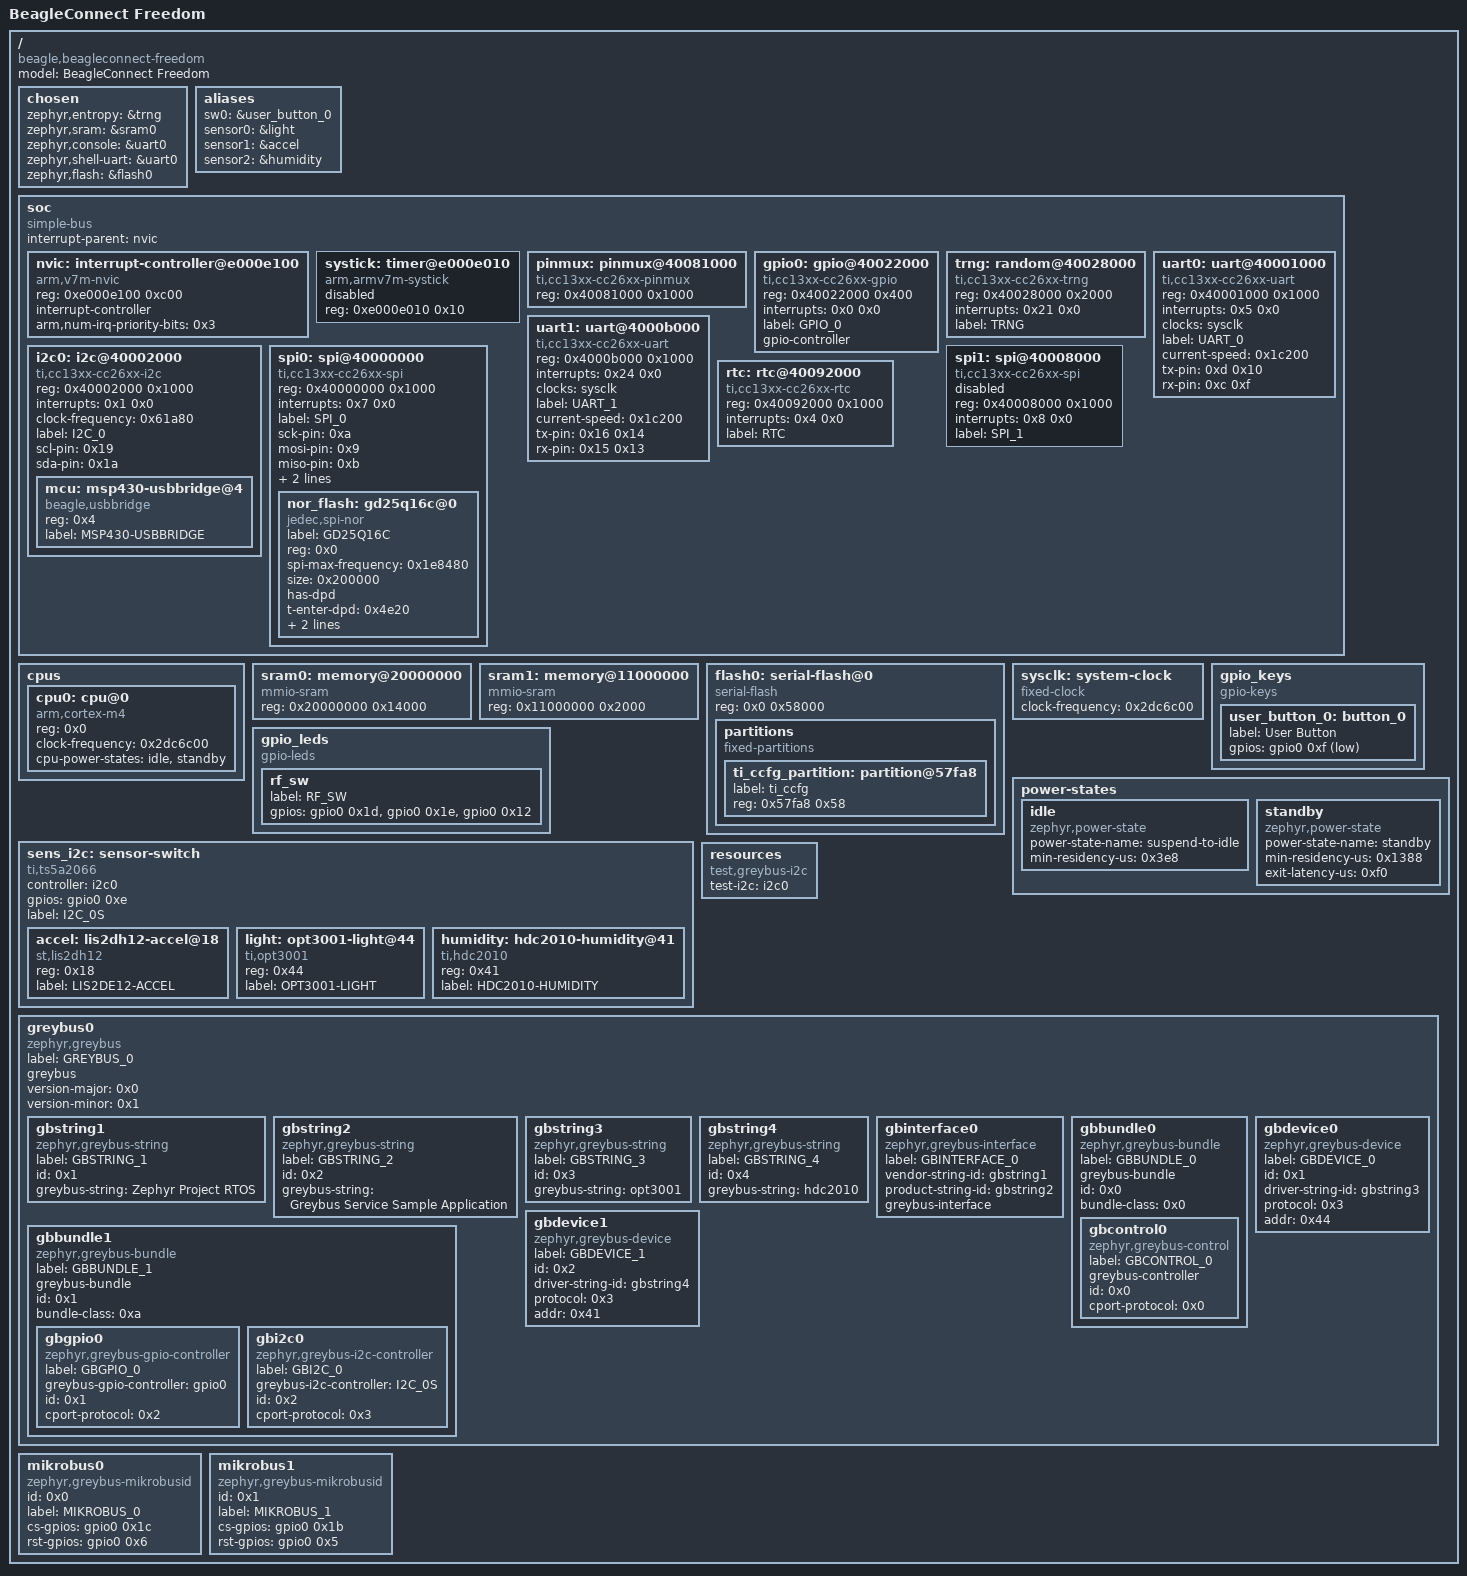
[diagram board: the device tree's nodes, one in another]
/dts-v1/;

/ {
	#address-cells = < 0x1 >;
	#size-cells = < 0x1 >;
	model = "BeagleConnect Freedom";
	compatible = "beagle,beagleconnect-freedom";
	chosen {
		zephyr,entropy = &trng;
		zephyr,sram = &sram0;
		zephyr,console = &uart0;
		zephyr,shell-uart = &uart0;
		zephyr,flash = &flash0;
	};
	aliases {
		sw0 = &user_button_0;
		sensor0 = &light;
		sensor1 = &accel;
		sensor2 = &humidity;
	};
	soc {
		#address-cells = < 0x1 >;
		#size-cells = < 0x1 >;
		compatible = "simple-bus";
		interrupt-parent = < &nvic >;
		ranges;
		nvic: interrupt-controller@e000e100 {
			#address-cells = < 0x1 >;
			compatible = "arm,v7m-nvic";
			reg = < 0xe000e100 0xc00 >;
			interrupt-controller;
			#interrupt-cells = < 0x2 >;
			arm,num-irq-priority-bits = < 0x3 >;
			phandle = < 0x1 >;
		};
		systick: timer@e000e010 {
			compatible = "arm,armv7m-systick";
			reg = < 0xe000e010 0x10 >;
			status = "disabled";
		};
		pinmux: pinmux@40081000 {
			compatible = "ti,cc13xx-cc26xx-pinmux";
			reg = < 0x40081000 0x1000 >;
		};
		gpio0: gpio@40022000 {
			compatible = "ti,cc13xx-cc26xx-gpio";
			reg = < 0x40022000 0x400 >;
			interrupts = < 0x0 0x0 >;
			status = "okay";
			label = "GPIO_0";
			gpio-controller;
			#gpio-cells = < 0x2 >;
			phandle = < 0x3 >;
		};
		trng: random@40028000 {
			compatible = "ti,cc13xx-cc26xx-trng";
			reg = < 0x40028000 0x2000 >;
			interrupts = < 0x21 0x0 >;
			status = "okay";
			label = "TRNG";
		};
		uart0: uart@40001000 {
			compatible = "ti,cc13xx-cc26xx-uart";
			reg = < 0x40001000 0x1000 >;
			interrupts = < 0x5 0x0 >;
			clocks = < &sysclk >;
			status = "okay";
			label = "UART_0";
			current-speed = < 0x1c200 >;
			tx-pin = < 0xd 0x10 >;
			rx-pin = < 0xc 0xf >;
		};
		uart1: uart@4000b000 {
			compatible = "ti,cc13xx-cc26xx-uart";
			reg = < 0x4000b000 0x1000 >;
			interrupts = < 0x24 0x0 >;
			clocks = < &sysclk >;
			status = "okay";
			label = "UART_1";
			current-speed = < 0x1c200 >;
			tx-pin = < 0x16 0x14 >;
			rx-pin = < 0x15 0x13 >;
		};
		i2c0: i2c@40002000 {
			compatible = "ti,cc13xx-cc26xx-i2c";
			#address-cells = < 0x1 >;
			#size-cells = < 0x0 >;
			reg = < 0x40002000 0x1000 >;
			interrupts = < 0x1 0x0 >;
			clock-frequency = < 0x61a80 >;
			status = "okay";
			label = "I2C_0";
			scl-pin = < 0x19 >;
			sda-pin = < 0x1a >;
			phandle = < 0x6 >;
			mcu: msp430-usbbridge@4 {
				compatible = "beagle,usbbridge";
				reg = < 0x4 >;
				label = "MSP430-USBBRIDGE";
			};
		};
		spi0: spi@40000000 {
			compatible = "ti,cc13xx-cc26xx-spi";
			#address-cells = < 0x1 >;
			#size-cells = < 0x0 >;
			reg = < 0x40000000 0x1000 >;
			interrupts = < 0x7 0x0 >;
			status = "okay";
			label = "SPI_0";
			sck-pin = < 0xa >;
			mosi-pin = < 0x9 >;
			miso-pin = < 0xb >;
			cs-gpios = < &gpio0 0x8 0x1 >, < &gpio0 0x1c 0x1 >, < &gpio0 0x1b 0x1 >;
			nor_flash: gd25q16c@0 {
				compatible = "jedec,spi-nor";
				label = "GD25Q16C";
				reg = < 0x0 >;
				spi-max-frequency = < 0x1e8480 >;
				size = < 0x200000 >;
				has-dpd;
				t-enter-dpd = < 0x4e20 >;
				t-exit-dpd = < 0x186a0 >;
				jedec-id = [ C8 40 15 ];
			};
		};
		spi1: spi@40008000 {
			compatible = "ti,cc13xx-cc26xx-spi";
			#address-cells = < 0x1 >;
			#size-cells = < 0x0 >;
			reg = < 0x40008000 0x1000 >;
			interrupts = < 0x8 0x0 >;
			status = "disabled";
			label = "SPI_1";
		};
		rtc: rtc@40092000 {
			compatible = "ti,cc13xx-cc26xx-rtc";
			reg = < 0x40092000 0x1000 >;
			interrupts = < 0x4 0x0 >;
			status = "okay";
			label = "RTC";
		};
	};
	cpus {
		#address-cells = < 0x1 >;
		#size-cells = < 0x0 >;
		cpu0: cpu@0 {
			device_type = "cpu";
			compatible = "arm,cortex-m4";
			reg = < 0x0 >;
			clock-frequency = < 0x2dc6c00 >;
			cpu-power-states = < &idle &standby >;
		};
	};
	sram0: memory@20000000 {
		compatible = "mmio-sram";
		reg = < 0x20000000 0x14000 >;
	};
	sram1: memory@11000000 {
		compatible = "mmio-sram";
		reg = < 0x11000000 0x2000 >;
	};
	flash0: serial-flash@0 {
		compatible = "serial-flash";
		reg = < 0x0 0x58000 >;
		status = "okay";
		partitions {
			compatible = "fixed-partitions";
			#address-cells = < 0x1 >;
			#size-cells = < 0x1 >;
			ti_ccfg_partition: partition@57fa8 {
				label = "ti_ccfg";
				reg = < 0x57fa8 0x58 >;
			};
		};
	};
	sysclk: system-clock {
		compatible = "fixed-clock";
		clock-frequency = < 0x2dc6c00 >;
		#clock-cells = < 0x0 >;
		phandle = < 0x2 >;
	};
	gpio_keys {
		compatible = "gpio-keys";
		user_button_0: button_0 {
			label = "User Button";
			gpios = < &gpio0 0xf 0x1 >;
		};
	};
	gpio_leds {
		compatible = "gpio-leds";
		rf_sw: rf_sw {
			label = "RF_SW";
			gpios = < &gpio0 0x1d 0x0 >, < &gpio0 0x1e 0x0 >, < &gpio0 0x12 0x0 >;
		};
	};
	sens_i2c: sensor-switch {
		compatible = "ti,ts5a2066";
		#address-cells = < 0x1 >;
		#size-cells = < 0x0 >;
		controller = < &i2c0 >;
		gpios = < &gpio0 0xe 0x0 >;
		label = "I2C_0S";
		accel: lis2dh12-accel@18 {
			compatible = "st,lis2dh12", "st,lis2dh", "st,lis2de12";
			reg = < 0x18 >;
			label = "LIS2DE12-ACCEL";
		};
		light: opt3001-light@44 {
			compatible = "ti,opt3001";
			reg = < 0x44 >;
			label = "OPT3001-LIGHT";
		};
		humidity: hdc2010-humidity@41 {
			compatible = "ti,hdc2010";
			reg = < 0x41 >;
			label = "HDC2010-HUMIDITY";
		};
	};
	power-states {
		idle: idle {
			compatible = "zephyr,power-state";
			power-state-name = "suspend-to-idle";
			min-residency-us = < 0x3e8 >;
			phandle = < 0x4 >;
		};
		standby: standby {
			compatible = "zephyr,power-state";
			power-state-name = "standby";
			min-residency-us = < 0x1388 >;
			exit-latency-us = < 0xf0 >;
			phandle = < 0x5 >;
		};
	};
	resources {
		compatible = "test,greybus-i2c";
		test-i2c = < &i2c0 >;
	};
	greybus0: greybus0 {
		compatible = "zephyr,greybus";
		label = "GREYBUS_0";
		greybus;
		status = "okay";
		version-major = < 0x0 >;
		version-minor = < 0x1 >;
		gbstring1: gbstring1 {
			label = "GBSTRING_1";
			status = "okay";
			compatible = "zephyr,greybus-string";
			id = < 0x1 >;
			greybus-string = "Zephyr Project RTOS";
			phandle = < 0x7 >;
		};
		gbstring2: gbstring2 {
			label = "GBSTRING_2";
			status = "okay";
			compatible = "zephyr,greybus-string";
			id = < 0x2 >;
			greybus-string = "Greybus Service Sample Application";
			phandle = < 0x8 >;
		};
		gbstring3: gbstring3 {
			label = "GBSTRING_3";
			status = "okay";
			compatible = "zephyr,greybus-string";
			id = < 0x3 >;
			greybus-string = "opt3001";
			phandle = < 0x9 >;
		};
		gbstring4: gbstring4 {
			label = "GBSTRING_4";
			status = "okay";
			compatible = "zephyr,greybus-string";
			id = < 0x4 >;
			greybus-string = "hdc2010";
			phandle = < 0xa >;
		};
		gbinterface0 {
			label = "GBINTERFACE_0";
			status = "okay";
			compatible = "zephyr,greybus-interface";
			vendor-string-id = < &gbstring1 >;
			product-string-id = < &gbstring2 >;
			greybus-interface;
		};
		gbbundle0 {
			label = "GBBUNDLE_0";
			status = "okay";
			compatible = "zephyr,greybus-bundle";
			greybus-bundle;
			id = < 0x0 >;
			bundle-class = < 0x0 >;
			gbcontrol0 {
				label = "GBCONTROL_0";
				status = "okay";
				compatible = "zephyr,greybus-control";
				greybus-controller;
				id = < 0x0 >;
				cport-protocol = < 0x0 >;
			};
		};
		gbbundle1 {
			label = "GBBUNDLE_1";
			status = "okay";
			compatible = "zephyr,greybus-bundle";
			greybus-bundle;
			id = < 0x1 >;
			bundle-class = < 0xa >;
			gbgpio0 {
				label = "GBGPIO_0";
				status = "okay";
				compatible = "zephyr,greybus-gpio-controller";
				greybus-gpio-controller = < &gpio0 >;
				id = < 0x1 >;
				cport-protocol = < 0x2 >;
			};
			gbi2c0 {
				label = "GBI2C_0";
				status = "okay";
				compatible = "zephyr,greybus-i2c-controller";
				greybus-i2c-controller = "I2C_0S";
				id = < 0x2 >;
				cport-protocol = < 0x3 >;
			};
		};
		gbdevice0 {
			label = "GBDEVICE_0";
			status = "okay";
			compatible = "zephyr,greybus-device";
			id = < 0x1 >;
			driver-string-id = < &gbstring3 >;
			protocol = < 0x3 >;
			addr = < 0x44 >;
		};
		gbdevice1 {
			label = "GBDEVICE_1";
			status = "okay";
			compatible = "zephyr,greybus-device";
			id = < 0x2 >;
			driver-string-id = < &gbstring4 >;
			protocol = < 0x3 >;
			addr = < 0x41 >;
		};
	};
	mikrobus0: mikrobus0 {
		id = < 0x0 >;
		compatible = "zephyr,greybus-mikrobusid";
		label = "MIKROBUS_0";
		cs-gpios = < &gpio0 0x1c 0x0 >;
		rst-gpios = < &gpio0 0x6 0x0 >;
	};
	mikrobus1: mikrobus1 {
		id = < 0x1 >;
		compatible = "zephyr,greybus-mikrobusid";
		label = "MIKROBUS_1";
		cs-gpios = < &gpio0 0x1b 0x0 >;
		rst-gpios = < &gpio0 0x5 0x0 >;
	};
};
